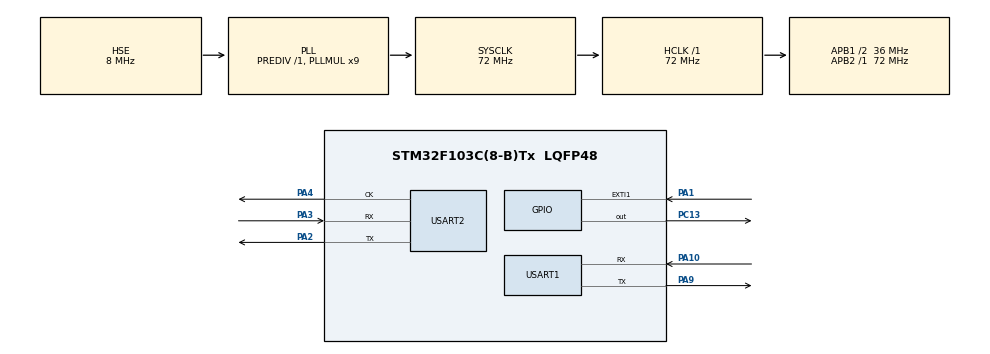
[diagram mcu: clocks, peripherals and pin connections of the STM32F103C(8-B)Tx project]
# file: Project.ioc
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Dma.Request0=USART1_TX
Dma.Request1=USART2_RX
Dma.Request2=USART2_TX
Dma.USART1_TX.0.Direction=DMA_MEMORY_TO_PERIPH
Dma.USART1_TX.0.Instance=DMA1_Channel4
Dma.USART1_TX.0.MemDataAlignment=DMA_MDATAALIGN_BYTE
Dma.USART1_TX.0.MemInc=DMA_MINC_ENABLE
Dma.USART1_TX.0.Mode=DMA_NORMAL
Dma.USART1_TX.0.PeriphDataAlignment=DMA_PDATAALIGN_BYTE
Dma.USART1_TX.0.PeriphInc=DMA_PINC_DISABLE
Dma.USART1_TX.0.Priority=DMA_PRIORITY_LOW
Dma.USART2_RX.1.Direction=DMA_PERIPH_TO_MEMORY
Dma.USART2_RX.1.Instance=DMA1_Channel6
Dma.USART2_RX.1.MemDataAlignment=DMA_MDATAALIGN_BYTE
Dma.USART2_RX.1.MemInc=DMA_MINC_ENABLE
Dma.USART2_RX.1.Mode=DMA_NORMAL
Dma.USART2_RX.1.PeriphDataAlignment=DMA_PDATAALIGN_BYTE
Dma.USART2_RX.1.PeriphInc=DMA_PINC_DISABLE
Dma.USART2_RX.1.Priority=DMA_PRIORITY_LOW
Dma.USART2_TX.2.Direction=DMA_MEMORY_TO_PERIPH
Dma.USART2_TX.2.Instance=DMA1_Channel7
Dma.USART2_TX.2.MemDataAlignment=DMA_MDATAALIGN_BYTE
Dma.USART2_TX.2.MemInc=DMA_MINC_ENABLE
Dma.USART2_TX.2.Mode=DMA_NORMAL
Dma.USART2_TX.2.PeriphDataAlignment=DMA_PDATAALIGN_BYTE
Dma.USART2_TX.2.PeriphInc=DMA_PINC_DISABLE
Dma.USART2_TX.2.Priority=DMA_PRIORITY_LOW
FREERTOS.Tasks01=defaultTask,24,128,StartDefaultTask,Default,NULL,Dynamic,NULL,NULL
FREERTOS.configUSE_TIMERS=1
Mcu.Family=STM32F1
Mcu.Name=STM32F103C(8-B)Tx
Mcu.Package=LQFP48
NVIC.DMA1_Channel4_IRQn=true\:5\:0\:false\:false\:true\:true\:false\:true\:true
NVIC.DMA1_Channel6_IRQn=true\:5\:0\:false\:false\:true\:true\:false\:true\:true
NVIC.DMA1_Channel7_IRQn=true\:5\:0\:false\:false\:true\:true\:false\:true\:true
NVIC.EXTI1_IRQn=true\:5\:0\:false\:false\:true\:true\:true\:true\:true
NVIC.PriorityGroup=NVIC_PRIORITYGROUP_4
NVIC.TIM1_UP_IRQn=true\:15\:0\:false\:false\:true\:false\:false\:true\:true
NVIC.TIM2_IRQn=true\:5\:0\:false\:false\:true\:true\:true\:true\:true
NVIC.TIM3_IRQn=true\:5\:0\:false\:false\:true\:true\:true\:true\:true
NVIC.TimeBase=TIM1_UP_IRQn
NVIC.TimeBaseIP=TIM1
NVIC.USART1_IRQn=true\:5\:0\:false\:false\:true\:true\:false\:true\:true
NVIC.USART2_IRQn=true\:5\:0\:false\:false\:true\:true\:true\:true\:true
PA0-WKUP.Mode=SYS_WakeUp0
PA0-WKUP.Signal=SYS_WKUP
PA1.Signal=GPXTI1
PA10.Mode=Asynchronous
PA10.Signal=USART1_RX
PA13.Mode=Serial_Wire
PA13.Signal=SYS_JTMS-SWDIO
PA14.Mode=Serial_Wire
PA14.Signal=SYS_JTCK-SWCLK
PA2.Mode=Synchronous
PA2.Signal=USART2_TX
PA3.Mode=Synchronous
PA3.Signal=USART2_RX
PA4.Mode=Synchronous
PA4.Signal=USART2_CK
PA9.Mode=Asynchronous
PA9.Signal=USART1_TX
PC13-TAMPER-RTC.Signal=GPIO_Output
PC14-OSC32_IN.Mode=LSE-External-Oscillator
PC14-OSC32_IN.Signal=RCC_OSC32_IN
PC15-OSC32_OUT.Mode=LSE-External-Oscillator
PC15-OSC32_OUT.Signal=RCC_OSC32_OUT
PD0-OSC_IN.Mode=HSE-External-Oscillator
PD0-OSC_IN.Signal=RCC_OSC_IN
PD1-OSC_OUT.Mode=HSE-External-Oscillator
PD1-OSC_OUT.Signal=RCC_OSC_OUT
ProjectManager.HeapSize=0x200
ProjectManager.StackSize=0x400
ProjectManager.TargetToolchain=MDK-ARM V5.32
RCC.AHBFreq_Value=72000000
RCC.APB1CLKDivider=RCC_HCLK_DIV2
RCC.APB1Freq_Value=36000000
RCC.APB1TimFreq_Value=72000000
RCC.APB2Freq_Value=72000000
RCC.APB2TimFreq_Value=72000000
RCC.HCLKFreq_Value=72000000
RCC.PLLMUL=RCC_PLL_MUL9
RCC.PLLSourceVirtual=RCC_PLLSOURCE_HSE
RCC.SYSCLKFreq_VALUE=72000000
RCC.SYSCLKSource=RCC_SYSCLKSOURCE_PLLCLK
RCC.USBFreq_Value=72000000
TIM2.AutoReloadPreload=TIM_AUTORELOAD_PRELOAD_ENABLE
TIM2.Period=1000
TIM2.Prescaler=72
TIM3.Period=1000
TIM3.Prescaler=72
USART1.VirtualMode=VM_ASYNC
USART2.VirtualMode=VM_SYNC
VP_FREERTOS_VS_CMSIS_V2.Mode=CMSIS_V2
VP_SYS_VS_tim1.Mode=TIM1
VP_TIM2_VS_ClockSourceINT.Mode=Internal
VP_TIM3_VS_ClockSourceINT.Mode=Internal
board=custom

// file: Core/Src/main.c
/* USER CODE BEGIN Header */
/**
 ******************************************************************************
 * @file           : main.c
 * @brief          : Main program body
 ******************************************************************************
 * @attention
 *
 * Copyright (c) 2025 STMicroelectronics.
 * All rights reserved.
 *
 * This software is licensed under terms that can be found in the LICENSE file
 * in the root directory of this software component.
 * If no LICENSE file comes with this software, it is provided AS-IS.
 *
 ******************************************************************************
 */
/* USER CODE END Header */
#include "main.h"
#include "cmsis_os2.h"
#include "dma.h"
#include "tim.h"
#include "usart.h"
#include "gpio.h"
// #include "SEGGER/RTT/SEGGER_RTT.h"

/* USER CODE BEGIN Includes */

#include "core.h"
#include "bsp/bsp_dwt.h"
/* USER CODE END Includes */

void SystemClock_Config(void);
void MX_FREERTOS_Init(void);

int main(void)
{

  /* MCU Configuration--------------------------------------------------------*/

  /* Reset of all peripherals, Initializes the Flash interface and the Systick. */

  HAL_Init();

  /* Configure the system clock */
  SystemClock_Config();

  /* USER CODE BEGIN SysInit */
    // __set_PRIMASK(0);
    NVIC_SetPriorityGrouping(0);
    bsp_InitDWT();
  /* USER CODE END SysInit */

  /* Initialize all configured peripherals */
  MX_GPIO_Init();
  MX_DMA_Init();
  MX_USART1_UART_Init();
  MX_USART2_Init();
  MX_TIM2_Init();
  MX_TIM3_Init();

  /* Init scheduler */
  osKernelInitialize();  /* Call init function for freertos objects (in cmsis_os2.c) */
  MX_FREERTOS_Init();

  /* Start scheduler */
  osKernelStart();

  /* We should never get here as control is now taken by the scheduler */

  /* Infinite loop */
    while (1) {

    }
}

void SystemClock_Config(void)
{
  RCC_OscInitTypeDef RCC_OscInitStruct = {0};
  RCC_ClkInitTypeDef RCC_ClkInitStruct = {0};

  /** Initializes the RCC Oscillators according to the specified parameters
  * in the RCC_OscInitTypeDef structure.
  */
  RCC_OscInitStruct.OscillatorType = RCC_OSCILLATORTYPE_HSE;
  RCC_OscInitStruct.HSEState = RCC_HSE_ON;
  RCC_OscInitStruct.HSEPredivValue = RCC_HSE_PREDIV_DIV1;
  RCC_OscInitStruct.HSIState = RCC_HSI_ON;
  RCC_OscInitStruct.PLL.PLLState = RCC_PLL_ON;
  RCC_OscInitStruct.PLL.PLLSource = RCC_PLLSOURCE_HSE;
  RCC_OscInitStruct.PLL.PLLMUL = RCC_PLL_MUL9;
  if (HAL_RCC_OscConfig(&RCC_OscInitStruct) != HAL_OK)
  {
    Error_Handler();
  }

  /** Initializes the CPU, AHB and APB buses clocks
  */
  RCC_ClkInitStruct.ClockType = RCC_CLOCKTYPE_HCLK|RCC_CLOCKTYPE_SYSCLK
                              |RCC_CLOCKTYPE_PCLK1|RCC_CLOCKTYPE_PCLK2;
  RCC_ClkInitStruct.SYSCLKSource = RCC_SYSCLKSOURCE_PLLCLK;
  RCC_ClkInitStruct.AHBCLKDivider = RCC_SYSCLK_DIV1;
  RCC_ClkInitStruct.APB1CLKDivider = RCC_HCLK_DIV2;
  RCC_ClkInitStruct.APB2CLKDivider = RCC_HCLK_DIV1;

  if (HAL_RCC_ClockConfig(&RCC_ClkInitStruct, FLASH_LATENCY_2) != HAL_OK)
  {
    Error_Handler();
  }
}

void HAL_TIM_PeriodElapsedCallback(TIM_HandleTypeDef *htim)
{
  if (htim->Instance == TIM1)
  {
    HAL_IncTick();
  }
}

void Error_Handler(void)
{
    __disable_irq();
    while (1) {
    }
}

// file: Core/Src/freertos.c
/* USER CODE BEGIN Header */
/**
 ******************************************************************************
 * File Name          : freertos.c
 * Description        : Code for freertos applications
 ******************************************************************************
 * @attention
 *
 * Copyright (c) 2025 STMicroelectronics.
 * All rights reserved.
 *
 * This software is licensed under terms that can be found in the LICENSE file
 * in the root directory of this software component.
 * If no LICENSE file comes with this software, it is provided AS-IS.
 *
 ******************************************************************************
 */
/* USER CODE END Header */

#include "FreeRTOS.h"
#include "task.h"
#include "main.h"
#include "cmsis_os2.h"

/* USER CODE BEGIN Variables */
#define HEAP_ADDRESS 0x20002000
uint8_t ucHeap[configTOTAL_HEAP_SIZE] __attribute__((at(HEAP_ADDRESS)));

/* USER CODE END Variables */
/* Definitions for defaultTask */
osThreadId_t defaultTaskHandle;
const osThreadAttr_t defaultTask_attributes = {
  .name = "defaultTask",
  .stack_size = 128 * 4,
  .priority = (osPriority_t) osPriorityNormal,
};

/* USER CODE BEGIN FunctionPrototypes */

/* GetIdleTaskMemory prototype (linked to static allocation support) */
// void vApplicationGetIdleTaskMemory(StaticTask_t **ppxIdleTaskTCBBuffer,
//                                    StackType_t **ppxIdleTaskStackBuffer,
//                                    uint32_t *pulIdleTaskStackSize);

/* GetTimerTaskMemory prototype (linked to static allocation support) */
// void vApplicationGetTimerTaskMemory(StaticTask_t **ppxTimerTaskTCBBuffer,
//                                     StackType_t **ppxTimerTaskStackBuffer,
//                                     uint32_t *pulTimerTaskStackSize);

/* USER CODE BEGIN GET_IDLE_TASK_MEMORY */
// static StaticTask_t xIdleTaskTCBBuffer;
// static StackType_t xIdleStack[configMINIMAL_STACK_SIZE];

// void vApplicationGetIdleTaskMemory(StaticTask_t **ppxIdleTaskTCBBuffer,
//                                    StackType_t **ppxIdleTaskStackBuffer,
//                                    uint32_t *pulIdleTaskStackSize) {
//     *ppxIdleTaskTCBBuffer = &xIdleTaskTCBBuffer;
//     *ppxIdleTaskStackBuffer = &xIdleStack[0];
//     *pulIdleTaskStackSize = configMINIMAL_STACK_SIZE;
//     /* place for user code */
// }

// StaticTask_t xTimerTaskTCBBuffer;
// StackType_t xTimerTaskStack[configTIMER_TASK_STACK_DEPTH];

// void vApplicationGetTimerTaskMemory(StaticTask_t **ppxTimerTaskTCBBuffer,
//                                     StackType_t **ppxTimerTaskStackBuffer,
//                                     uint32_t *pulTimerTaskStackSize) {
//     *ppxTimerTaskTCBBuffer = &xTimerTaskTCBBuffer;
//     *ppxTimerTaskStackBuffer = &xTimerTaskStack[0];
//     *pulTimerTaskStackSize = configTIMER_TASK_STACK_DEPTH;
// }

/* USER CODE END FunctionPrototypes */

void StartDefaultTask(void *argument);

void MX_FREERTOS_Init(void); /* (MISRA C 2004 rule 8.1) */

void MX_FREERTOS_Init(void) {

  /* Create the thread(s) */
  /* creation of defaultTask */
  defaultTaskHandle = osThreadNew(StartDefaultTask, NULL, &defaultTask_attributes);

}

__weak void StartDefaultTask(void *argument)
{
    for (;;) {
    }
}
